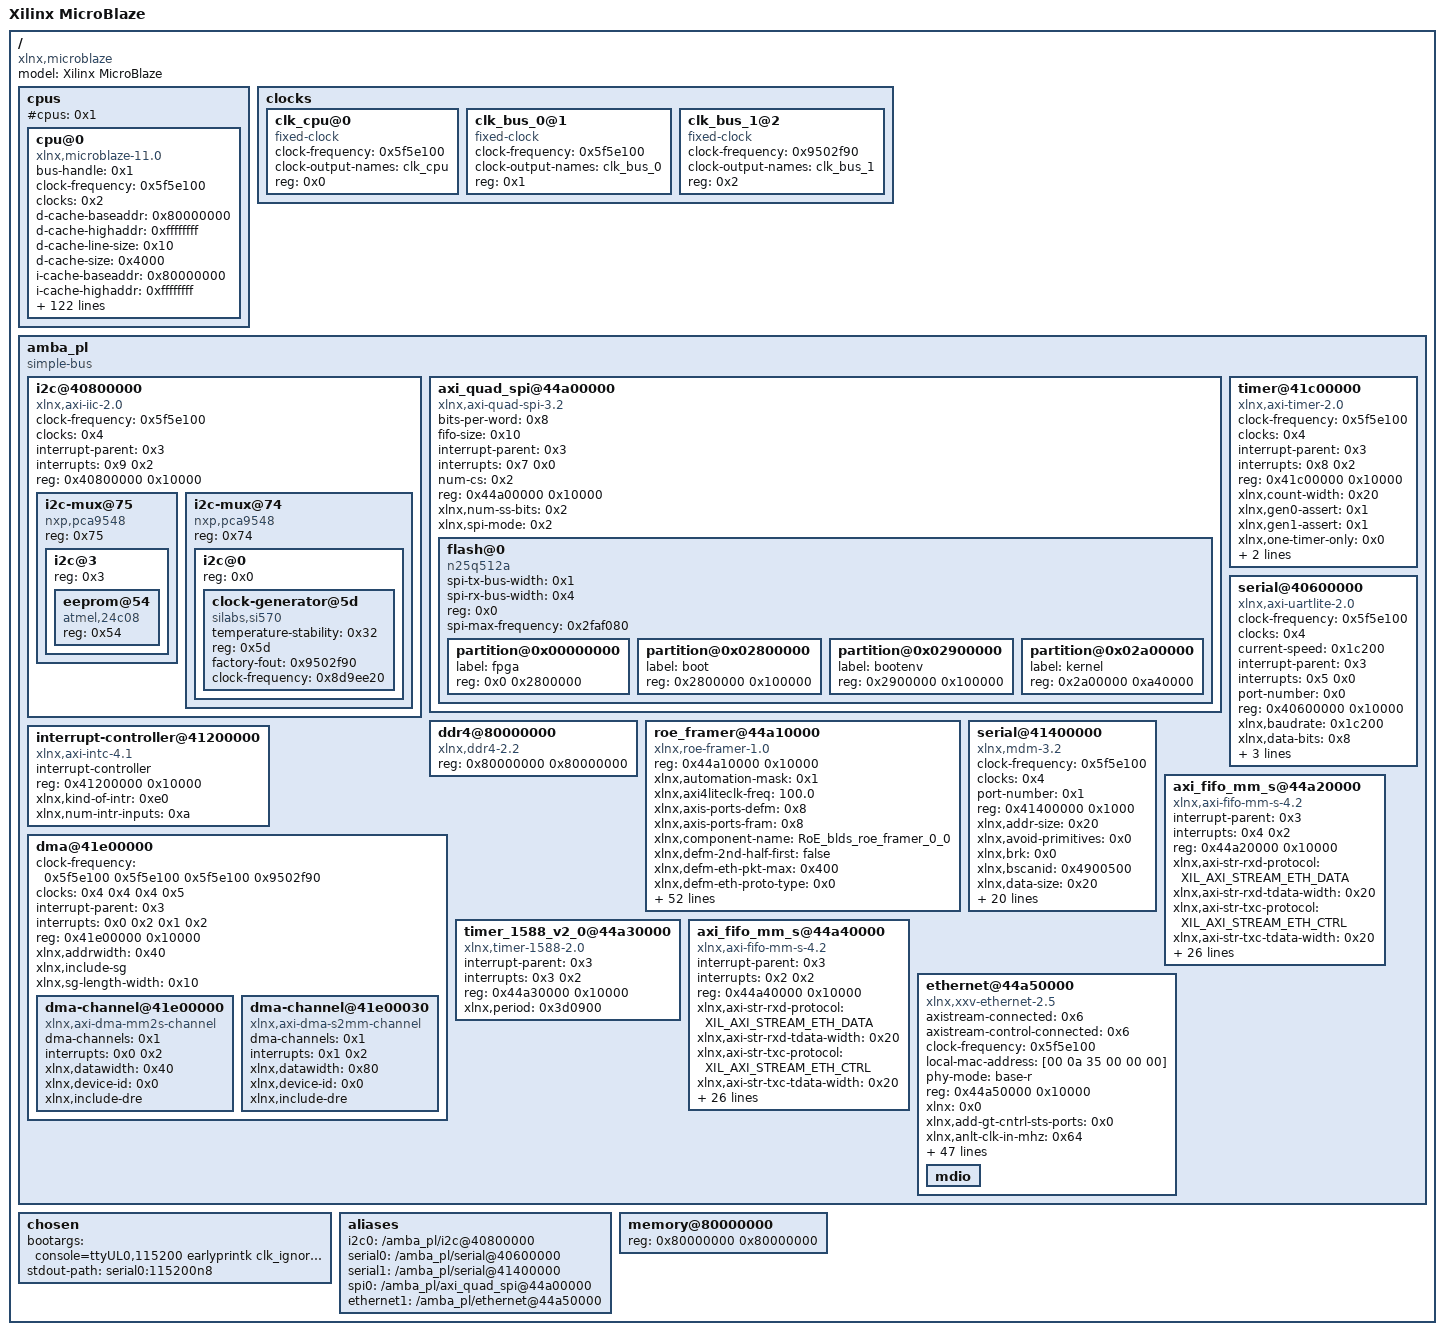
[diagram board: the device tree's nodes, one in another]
/dts-v1/;

/ {
	#address-cells = <0x1>;
	#size-cells = <0x1>;
	compatible = "xlnx,microblaze";
	model = "Xilinx MicroBlaze";

	cpus {
		#address-cells = <0x1>;
		#cpus = <0x1>;
		#size-cells = <0x0>;

		cpu@0 {
			bus-handle = <0x1>;
			clock-frequency = <0x5f5e100>;
			clocks = <0x2>;
			compatible = "xlnx,microblaze-11.0";
			d-cache-baseaddr = <0x80000000>;
			d-cache-highaddr = <0xffffffff>;
			d-cache-line-size = <0x10>;
			d-cache-size = <0x4000>;
			device_type = "cpu";
			i-cache-baseaddr = <0x80000000>;
			i-cache-highaddr = <0xffffffff>;
			i-cache-line-size = <0x20>;
			i-cache-size = <0x4000>;
			interrupt-handle = <0x3>;
			model = "microblaze,11.0";
			reg = <0x0>;
			timebase-frequency = <0x5f5e100>;
			xlnx,addr-size = <0x20>;
			xlnx,addr-tag-bits = <0x11>;
			xlnx,allow-dcache-wr = <0x1>;
			xlnx,allow-icache-wr = <0x1>;
			xlnx,area-optimized = <0x0>;
			xlnx,async-interrupt = <0x1>;
			xlnx,async-wakeup = <0x3>;
			xlnx,avoid-primitives = <0x0>;
			xlnx,base-vectors = <0x0>;
			xlnx,branch-target-cache-size = <0x0>;
			xlnx,cache-byte-size = <0x4000>;
			xlnx,d-axi = <0x1>;
			xlnx,d-lmb = <0x1>;
			xlnx,d-lmb-mon = <0x0>;
			xlnx,daddr-size = <0x20>;
			xlnx,data-size = <0x20>;
			xlnx,dc-axi-mon = <0x0>;
			xlnx,dcache-addr-tag = <0x11>;
			xlnx,dcache-always-used = <0x1>;
			xlnx,dcache-byte-size = <0x4000>;
			xlnx,dcache-data-width = <0x0>;
			xlnx,dcache-force-tag-lutram = <0x0>;
			xlnx,dcache-line-len = <0x4>;
			xlnx,dcache-use-writeback = <0x0>;
			xlnx,dcache-victims = <0x8>;
			xlnx,debug-counter-width = <0x20>;
			xlnx,debug-enabled = <0x1>;
			xlnx,debug-event-counters = <0x5>;
			xlnx,debug-external-trace = <0x0>;
			xlnx,debug-interface = <0x0>;
			xlnx,debug-latency-counters = <0x1>;
			xlnx,debug-profile-size = <0x0>;
			xlnx,debug-trace-async-reset = <0x0>;
			xlnx,debug-trace-size = <0x2000>;
			xlnx,div-zero-exception = <0x1>;
			xlnx,dp-axi-mon = <0x0>;
			xlnx,dynamic-bus-sizing = <0x0>;
			xlnx,ecc-use-ce-exception = <0x0>;
			xlnx,edge-is-positive = <0x1>;
			xlnx,enable-discrete-ports = <0x0>;
			xlnx,endianness = <0x1>;
			xlnx,fault-tolerant = <0x1>;
			xlnx,fpu-exception = <0x0>;
			xlnx,freq = <0x5f5e100>;
			xlnx,fsl-exception = <0x0>;
			xlnx,fsl-links = <0x0>;
			xlnx,i-axi = <0x1>;
			xlnx,i-lmb = <0x1>;
			xlnx,i-lmb-mon = <0x0>;
			xlnx,iaddr-size = <0x20>;
			xlnx,ic-axi-mon = <0x0>;
			xlnx,icache-always-used = <0x1>;
			xlnx,icache-data-width = <0x0>;
			xlnx,icache-force-tag-lutram = <0x0>;
			xlnx,icache-line-len = <0x8>;
			xlnx,icache-streams = <0x1>;
			xlnx,icache-victims = <0x8>;
			xlnx,ill-opcode-exception = <0x1>;
			xlnx,imprecise-exceptions = <0x0>;
			xlnx,instr-size = <0x20>;
			xlnx,interconnect = <0x2>;
			xlnx,interrupt-is-edge = <0x0>;
			xlnx,interrupt-mon = <0x0>;
			xlnx,ip-axi-mon = <0x0>;
			xlnx,lmb-data-size = <0x20>;
			xlnx,lockstep-master = <0x0>;
			xlnx,lockstep-select = <0x0>;
			xlnx,lockstep-slave = <0x0>;
			xlnx,mmu-dtlb-size = <0x4>;
			xlnx,mmu-itlb-size = <0x2>;
			xlnx,mmu-privileged-instr = <0x0>;
			xlnx,mmu-tlb-access = <0x3>;
			xlnx,mmu-zones = <0x2>;
			xlnx,num-sync-ff-clk = <0x2>;
			xlnx,num-sync-ff-clk-debug = <0x2>;
			xlnx,num-sync-ff-clk-irq = <0x1>;
			xlnx,num-sync-ff-dbg-clk = <0x1>;
			xlnx,num-sync-ff-dbg-trace-clk = <0x2>;
			xlnx,number-of-pc-brk = <0x1>;
			xlnx,number-of-rd-addr-brk = <0x0>;
			xlnx,number-of-wr-addr-brk = <0x0>;
			xlnx,opcode-0x0-illegal = <0x1>;
			xlnx,optimization = <0x0>;
			xlnx,pc-width = <0x20>;
			xlnx,piaddr-size = <0x20>;
			xlnx,pvr = <0x2>;
			xlnx,pvr-user1 = <0x0>;
			xlnx,pvr-user2 = <0x0>;
			xlnx,reset-msr = <0x0>;
			xlnx,reset-msr-bip = <0x0>;
			xlnx,reset-msr-dce = <0x0>;
			xlnx,reset-msr-ee = <0x0>;
			xlnx,reset-msr-eip = <0x0>;
			xlnx,reset-msr-ice = <0x0>;
			xlnx,reset-msr-ie = <0x0>;
			xlnx,sco = <0x0>;
			xlnx,trace = <0x0>;
			xlnx,unaligned-exceptions = <0x1>;
			xlnx,use-barrel = <0x1>;
			xlnx,use-branch-target-cache = <0x0>;
			xlnx,use-config-reset = <0x0>;
			xlnx,use-dcache = <0x1>;
			xlnx,use-div = <0x1>;
			xlnx,use-ext-brk = <0x0>;
			xlnx,use-ext-nm-brk = <0x0>;
			xlnx,use-extended-fsl-instr = <0x0>;
			xlnx,use-fpu = <0x0>;
			xlnx,use-hw-mul = <0x2>;
			xlnx,use-icache = <0x1>;
			xlnx,use-interrupt = <0x2>;
			xlnx,use-mmu = <0x3>;
			xlnx,use-msr-instr = <0x1>;
			xlnx,use-non-secure = <0x0>;
			xlnx,use-pcmp-instr = <0x1>;
			xlnx,use-reorder-instr = <0x1>;
			xlnx,use-stack-protection = <0x0>;
		};
	};

	clocks {
		#address-cells = <0x1>;
		#size-cells = <0x0>;

		clk_cpu@0 {
			#clock-cells = <0x0>;
			clock-frequency = <0x5f5e100>;
			clock-output-names = "clk_cpu";
			compatible = "fixed-clock";
			reg = <0x0>;
			linux,phandle = <0x2>;
			phandle = <0x2>;
		};

		clk_bus_0@1 {
			#clock-cells = <0x0>;
			clock-frequency = <0x5f5e100>;
			clock-output-names = "clk_bus_0";
			compatible = "fixed-clock";
			reg = <0x1>;
			linux,phandle = <0x4>;
			phandle = <0x4>;
		};

		clk_bus_1@2 {
			#clock-cells = <0x0>;
			clock-frequency = <0x9502f90>;
			clock-output-names = "clk_bus_1";
			compatible = "fixed-clock";
			reg = <0x2>;
			linux,phandle = <0x5>;
			phandle = <0x5>;
		};
	};

	amba_pl {
		#address-cells = <0x1>;
		#size-cells = <0x1>;
		compatible = "simple-bus";
		ranges;
		linux,phandle = <0x1>;
		phandle = <0x1>;

		i2c@40800000 {
			#address-cells = <0x1>;
			#size-cells = <0x0>;
			clock-frequency = <0x5f5e100>;
			clocks = <0x4>;
			compatible = "xlnx,axi-iic-2.0", "xlnx,xps-iic-2.00.a";
			interrupt-names = "iic2intc_irpt";
			interrupt-parent = <0x3>;
			interrupts = <0x9 0x2>;
			reg = <0x40800000 0x10000>;

			i2c-mux@75 {
				compatible = "nxp,pca9548";
				#address-cells = <0x1>;
				#size-cells = <0x0>;
				reg = <0x75>;

				i2c@3 {
					#address-cells = <0x1>;
					#size-cells = <0x0>;
					reg = <0x3>;

					eeprom@54 {
						compatible = "atmel,24c08";
						reg = <0x54>;
					};
				};
			};

			i2c-mux@74 {
				compatible = "nxp,pca9548";
				#address-cells = <0x1>;
				#size-cells = <0x0>;
				reg = <0x74>;

				i2c@0 {
					#address-cells = <0x1>;
					#size-cells = <0x0>;
					reg = <0x0>;

					clock-generator@5d {
						#clock-cells = <0x0>;
						compatible = "silabs,si570";
						temperature-stability = <0x32>;
						reg = <0x5d>;
						factory-fout = <0x9502f90>;
						clock-frequency = <0x8d9ee20>;
					};
				};
			};
		};

		axi_quad_spi@44a00000 {
			bits-per-word = <0x8>;
			compatible = "xlnx,axi-quad-spi-3.2", "xlnx,xps-spi-2.00.a";
			fifo-size = <0x10>;
			interrupt-names = "ip2intc_irpt";
			interrupt-parent = <0x3>;
			interrupts = <0x7 0x0>;
			num-cs = <0x2>;
			reg = <0x44a00000 0x10000>;
			xlnx,num-ss-bits = <0x2>;
			xlnx,spi-mode = <0x2>;
			#address-cells = <0x1>;
			#size-cells = <0x0>;

			flash@0 {
				compatible = "n25q512a", "micron,m25p80", "spi-flash";
				spi-tx-bus-width = <0x1>;
				spi-rx-bus-width = <0x4>;
				reg = <0x0>;
				#address-cells = <0x1>;
				#size-cells = <0x1>;
				spi-max-frequency = <0x2faf080>;

				partition@0x00000000 {
					label = "fpga";
					reg = <0x0 0x2800000>;
				};

				partition@0x02800000 {
					label = "boot";
					reg = <0x2800000 0x100000>;
				};

				partition@0x02900000 {
					label = "bootenv";
					reg = <0x2900000 0x100000>;
				};

				partition@0x02a00000 {
					label = "kernel";
					reg = <0x2a00000 0xa40000>;
				};
			};
		};

		timer@41c00000 {
			clock-frequency = <0x5f5e100>;
			clocks = <0x4>;
			compatible = "xlnx,axi-timer-2.0", "xlnx,xps-timer-1.00.a";
			interrupt-names = "interrupt";
			interrupt-parent = <0x3>;
			interrupts = <0x8 0x2>;
			reg = <0x41c00000 0x10000>;
			xlnx,count-width = <0x20>;
			xlnx,gen0-assert = <0x1>;
			xlnx,gen1-assert = <0x1>;
			xlnx,one-timer-only = <0x0>;
			xlnx,trig0-assert = <0x1>;
			xlnx,trig1-assert = <0x1>;
		};

		serial@40600000 {
			clock-frequency = <0x5f5e100>;
			clocks = <0x4>;
			compatible = "xlnx,axi-uartlite-2.0", "xlnx,xps-uartlite-1.00.a";
			current-speed = <0x1c200>;
			device_type = "serial";
			interrupt-names = "interrupt";
			interrupt-parent = <0x3>;
			interrupts = <0x5 0x0>;
			port-number = <0x0>;
			reg = <0x40600000 0x10000>;
			xlnx,baudrate = <0x1c200>;
			xlnx,data-bits = <0x8>;
			xlnx,odd-parity = <0x0>;
			xlnx,s-axi-aclk-freq-hz-d = "100.0";
			xlnx,use-parity = <0x0>;
		};

		ddr4@80000000 {
			compatible = "xlnx,ddr4-2.2";
			reg = <0x80000000 0x80000000>;
		};

		roe_framer@44a10000 {
			compatible = "xlnx,roe-framer-1.0";
			reg = <0x44a10000 0x10000>;
			xlnx,automation-mask = <0x1>;
			xlnx,axi4liteclk-freq = "100.0";
			xlnx,axis-ports-defm = <0x8>;
			xlnx,axis-ports-fram = <0x8>;
			xlnx,component-name = "RoE_blds_roe_framer_0_0";
			xlnx,defm-2nd-half-first = "false";
			xlnx,defm-eth-pkt-max = <0x400>;
			xlnx,defm-eth-proto-type = <0x0>;
			xlnx,defm-ext-srf = "true";
			xlnx,defm-fd-en = "false";
			xlnx,defm-high-l-sn-cnt-pres = "false";
			xlnx,defm-high-l-sn-cnt-width = <0x10>;
			xlnx,defm-ipv4-dest-addr = <0x0>;
			xlnx,defm-ipv4-source-addr = <0x0>;
			xlnx,defm-ipv6-dest-addr = <0x0>;
			xlnx,defm-ipv6-source-addr = <0x0>;
			xlnx,defm-low-l-sn-cnt-pos = "false";
			xlnx,defm-low-l-sn-cnt-width = <0x10>;
			xlnx,defm-pdu = <0x400>;
			xlnx,defm-pkt-x-pdu = <0x1>;
			xlnx,defm-rtc-en = "false";
			xlnx,defm-rtc-len = <0x3c>;
			xlnx,defm-rwin = <0x1>;
			xlnx,defm-sn-reserved-bits = <0x0>;
			xlnx,defm-type2-mac-dest-addr = <0x0>;
			xlnx,defm-type2-mac-source-addr = <0x0>;
			xlnx,defm-vlan-enable = "false";
			xlnx,defm-vlantagcontent = <0x0>;
			xlnx,defmantennaclk-freq = "10.0";
			xlnx,externautomationtclargs = <0x0>;
			xlnx,externautomationtclscr = <0x0>;
			xlnx,fram-auto-start = "true";
			xlnx,fram-eth-pkt-max = <0x400>;
			xlnx,fram-eth-proto-type = <0x0>;
			xlnx,fram-ext-srf = "true";
			xlnx,fram-fd-en = "false";
			xlnx,fram-high-l-sn-cnt-pres = "false";
			xlnx,fram-high-l-sn-cnt-width = <0x10>;
			xlnx,fram-ipv4-dest-addr = <0x0>;
			xlnx,fram-ipv4-source-addr = <0x0>;
			xlnx,fram-ipv6-dest-addr = <0x0>;
			xlnx,fram-ipv6-source-addr = <0x0>;
			xlnx,fram-low-l-sn-cnt-pos = "false";
			xlnx,fram-low-l-sn-cnt-width = <0x10>;
			xlnx,fram-pdu = <0x400>;
			xlnx,fram-rtc-en = "false";
			xlnx,fram-rtc-len = <0x3c>;
			xlnx,fram-sn-reserved-bits = <0x0>;
			xlnx,fram-type2-mac-dest-addr = <0x0>;
			xlnx,fram-type2-mac-source-addr = <0x0>;
			xlnx,fram-vlan-enable = "false";
			xlnx,fram-vlantagcontent = <0x0>;
			xlnx,framantennaclk-freq = "10.0";
			xlnx,internal-bist-mode = <0x0>;
			xlnx,internalclk-freq = "156.25";
			xlnx,physical-ethernet-ports = <0x1>;
			xlnx,physical-ethernet-rate = "10G";
			xlnx,production-simulation = <0x0>;
			xlnx,tsn-support = <0x0>;
			xlnx,user-gpio-enable = "true";
		};

		serial@41400000 {
			clock-frequency = <0x5f5e100>;
			clocks = <0x4>;
			compatible = "xlnx,mdm-3.2", "xlnx,xps-uartlite-1.00.a";
			device_type = "serial";
			port-number = <0x1>;
			reg = <0x41400000 0x1000>;
			xlnx,addr-size = <0x20>;
			xlnx,avoid-primitives = <0x0>;
			xlnx,brk = <0x0>;
			xlnx,bscanid = <0x4900500>;
			xlnx,data-size = <0x20>;
			xlnx,dbg-mem-access = <0x0>;
			xlnx,dbg-reg-access = <0x0>;
			xlnx,debug-interface = <0x0>;
			xlnx,ext-trig-reset-value = <0xf1234>;
			xlnx,interconnect = <0x2>;
			xlnx,jtag-chain = <0x2>;
			xlnx,mb-dbg-ports = <0x1>;
			xlnx,trace-async-reset = <0x0>;
			xlnx,trace-clk-out-phase = <0x5a>;
			xlnx,trace-data-width = <0x20>;
			xlnx,trace-id = <0x6e>;
			xlnx,trace-output = <0x0>;
			xlnx,trace-protocol = <0x1>;
			xlnx,trig-in-ports = <0x1>;
			xlnx,trig-out-ports = <0x1>;
			xlnx,use-bscan = <0x0>;
			xlnx,use-config-reset = <0x0>;
			xlnx,use-cross-trigger = <0x0>;
			xlnx,use-uart = <0x1>;
			xlnx,xmtc = <0x0>;
		};

		interrupt-controller@41200000 {
			#interrupt-cells = <0x2>;
			compatible = "xlnx,axi-intc-4.1", "xlnx,xps-intc-1.00.a";
			interrupt-controller;
			reg = <0x41200000 0x10000>;
			xlnx,kind-of-intr = <0xe0>;
			xlnx,num-intr-inputs = <0xa>;
			linux,phandle = <0x3>;
			phandle = <0x3>;
		};

		dma@41e00000 {
			#dma-cells = <0x1>;
			clock-frequency = <0x5f5e100 0x5f5e100 0x5f5e100 0x9502f90>;
			clock-names = "s_axi_lite_aclk", "m_axi_sg_aclk", "m_axi_mm2s_aclk", "m_axi_s2mm_aclk";
			clocks = <0x4 0x4 0x4 0x5>;
			compatible = [00];
			interrupt-names = "mm2s_introut", "s2mm_introut";
			interrupt-parent = <0x3>;
			interrupts = <0x0 0x2 0x1 0x2>;
			reg = <0x41e00000 0x10000>;
			xlnx,addrwidth = <0x40>;
			xlnx,include-sg;
			xlnx,sg-length-width = <0x10>;
			linux,phandle = <0x6>;
			phandle = <0x6>;

			dma-channel@41e00000 {
				compatible = "xlnx,axi-dma-mm2s-channel";
				dma-channels = <0x1>;
				interrupts = <0x0 0x2>;
				xlnx,datawidth = <0x40>;
				xlnx,device-id = <0x0>;
				xlnx,include-dre;
			};

			dma-channel@41e00030 {
				compatible = "xlnx,axi-dma-s2mm-channel";
				dma-channels = <0x1>;
				interrupts = <0x1 0x2>;
				xlnx,datawidth = <0x80>;
				xlnx,device-id = <0x0>;
				xlnx,include-dre;
			};
		};

		axi_fifo_mm_s@44a20000 {
			compatible = "xlnx,axi-fifo-mm-s-4.2";
			interrupt-names = "interrupt";
			interrupt-parent = <0x3>;
			interrupts = <0x4 0x2>;
			reg = <0x44a20000 0x10000>;
			xlnx,axi-str-rxd-protocol = "XIL_AXI_STREAM_ETH_DATA";
			xlnx,axi-str-rxd-tdata-width = <0x20>;
			xlnx,axi-str-txc-protocol = "XIL_AXI_STREAM_ETH_CTRL";
			xlnx,axi-str-txc-tdata-width = <0x20>;
			xlnx,axi-str-txd-protocol = "XIL_AXI_STREAM_ETH_DATA";
			xlnx,axi-str-txd-tdata-width = <0x20>;
			xlnx,axis-tdest-width = <0x4>;
			xlnx,axis-tid-width = <0x4>;
			xlnx,axis-tuser-width = <0x4>;
			xlnx,data-interface-type = <0x0>;
			xlnx,has-axis-tdest = <0x0>;
			xlnx,has-axis-tid = <0x0>;
			xlnx,has-axis-tkeep = <0x0>;
			xlnx,has-axis-tstrb = <0x0>;
			xlnx,has-axis-tuser = <0x0>;
			xlnx,rx-fifo-depth = <0x200>;
			xlnx,rx-fifo-pe-threshold = <0x5>;
			xlnx,rx-fifo-pf-threshold = <0x1fb>;
			xlnx,s-axi-id-width = <0x4>;
			xlnx,s-axi4-data-width = <0x20>;
			xlnx,select-xpm = <0x0>;
			xlnx,tx-fifo-depth = <0x200>;
			xlnx,tx-fifo-pe-threshold = <0x5>;
			xlnx,tx-fifo-pf-threshold = <0x1fb>;
			xlnx,use-rx-cut-through = <0x0>;
			xlnx,use-rx-data = <0x1>;
			xlnx,use-tx-ctrl = <0x0>;
			xlnx,use-tx-cut-through = <0x0>;
			xlnx,use-tx-data = <0x0>;
			linux,phandle = <0x8>;
			phandle = <0x8>;
		};

		timer_1588_v2_0@44a30000 {
			compatible = "xlnx,timer-1588-2.0";
			interrupt-names = "interrupt";
			interrupt-parent = <0x3>;
			interrupts = <0x3 0x2>;
			reg = <0x44a30000 0x10000>;
			xlnx,period = <0x3d0900>;
		};

		axi_fifo_mm_s@44a40000 {
			compatible = "xlnx,axi-fifo-mm-s-4.2";
			interrupt-names = "interrupt";
			interrupt-parent = <0x3>;
			interrupts = <0x2 0x2>;
			reg = <0x44a40000 0x10000>;
			xlnx,axi-str-rxd-protocol = "XIL_AXI_STREAM_ETH_DATA";
			xlnx,axi-str-rxd-tdata-width = <0x20>;
			xlnx,axi-str-txc-protocol = "XIL_AXI_STREAM_ETH_CTRL";
			xlnx,axi-str-txc-tdata-width = <0x20>;
			xlnx,axi-str-txd-protocol = "XIL_AXI_STREAM_ETH_DATA";
			xlnx,axi-str-txd-tdata-width = <0x20>;
			xlnx,axis-tdest-width = <0x4>;
			xlnx,axis-tid-width = <0x4>;
			xlnx,axis-tuser-width = <0x4>;
			xlnx,data-interface-type = <0x0>;
			xlnx,has-axis-tdest = <0x0>;
			xlnx,has-axis-tid = <0x0>;
			xlnx,has-axis-tkeep = <0x0>;
			xlnx,has-axis-tstrb = <0x0>;
			xlnx,has-axis-tuser = <0x0>;
			xlnx,rx-fifo-depth = <0x200>;
			xlnx,rx-fifo-pe-threshold = <0x5>;
			xlnx,rx-fifo-pf-threshold = <0x1fb>;
			xlnx,s-axi-id-width = <0x4>;
			xlnx,s-axi4-data-width = <0x20>;
			xlnx,select-xpm = <0x0>;
			xlnx,tx-fifo-depth = <0x200>;
			xlnx,tx-fifo-pe-threshold = <0x5>;
			xlnx,tx-fifo-pf-threshold = <0x1fb>;
			xlnx,use-rx-cut-through = <0x0>;
			xlnx,use-rx-data = <0x1>;
			xlnx,use-tx-ctrl = <0x0>;
			xlnx,use-tx-cut-through = <0x0>;
			xlnx,use-tx-data = <0x1>;
			linux,phandle = <0x7>;
			phandle = <0x7>;
		};

		ethernet@44a50000 {
			axistream-connected = <0x6>;
			axistream-control-connected = <0x6>;
			clock-frequency = <0x5f5e100>;
			compatible = "xlnx,xxv-ethernet-2.5", "xlnx,xxv-ethernet-1.0";
			device_type = "network";
			local-mac-address = [00 0a 35 00 00 00];
			phy-mode = "base-r";
			reg = <0x44a50000 0x10000>;
			xlnx = <0x0>;
			xlnx,add-gt-cntrl-sts-ports = <0x0>;
			xlnx,anlt-clk-in-mhz = <0x64>;
			xlnx,axis-tdata-width = <0x40>;
			xlnx,axis-tkeep-width = <0x7>;
			xlnx,base-r-kr = "BASE-R";
			xlnx,clocking = "Asynchronous";
			xlnx,core = "Ethernet MAC+PCS/PMA 64-bit";
			xlnx,data-path-interface = "AXI Stream";
			xlnx,enable-datapath-parity = <0x0>;
			xlnx,enable-pipeline-reg = <0x0>;
			xlnx,enable-preemption = <0x0>;
			xlnx,enable-preemption-fifo = <0x0>;
			xlnx,enable-rx-flow-control-logic = <0x0>;
			xlnx,enable-time-stamping = <0x1>;
			xlnx,enable-tx-flow-control-logic = <0x0>;
			xlnx,enable-vlane-adjust-mode = <0x0>;
			xlnx,family-chk = "virtexuplus";
			xlnx,fast-sim-mode = <0x0>;
			xlnx,gt-diffctrl-width = <0x4>;
			xlnx,gt-drp-clk = "100.00";
			xlnx,gt-group-select = "Quad X0Y0";
			xlnx,gt-location = <0x1>;
			xlnx,gt-ref-clk-freq = "156.25";
			xlnx,gt-type = "GTY";
			xlnx,include-auto-neg-lt-logic = "None";
			xlnx,include-axi4-interface = <0x1>;
			xlnx,include-dre;
			xlnx,include-fec-logic = <0x0>;
			xlnx,include-rsfec-logic = <0x0>;
			xlnx,include-shared-logic = <0x1>;
			xlnx,include-user-fifo = <0x1>;
			xlnx,lane1-gt-loc = "X1Y48";
			xlnx,lane2-gt-loc = "NA";
			xlnx,lane3-gt-loc = "NA";
			xlnx,lane4-gt-loc = "NA";
			xlnx,line-rate = <0xa>;
			xlnx,mii-ctrl-width = <0x4>;
			xlnx,mii-data-width = <0x20>;
			xlnx,num-of-cores = <0x1>;
			xlnx,ptp-clocking-mode = <0x0>;
			xlnx,ptp-operation-mode = <0x2>;
			xlnx,runtime-switch = <0x0>;
			xlnx,rxmem = <0x2580>;
			xlnx,switch-1-10-25g = <0x0>;
			xlnx,tx-latency-adjust = <0x0>;
			xlnx,tx-total-bytes-width = <0x4>;
			xlnx,xgmii-interface = <0x1>;
			axififo-connected = <0x7>;
			xlnx,rxtsfifo = <0x8>;

			mdio {
				#address-cells = <0x1>;
				#size-cells = <0x0>;
			};
		};
	};

	chosen {
		bootargs = "console=ttyUL0,115200 earlyprintk clk_ignore_unused cpuidle.off=1 uio_pdrv_genirq.of_id=generic-uio mem=5G";
		stdout-path = "serial0:115200n8";
	};

	aliases {
		i2c0 = "/amba_pl/i2c@40800000";
		serial0 = "/amba_pl/serial@40600000";
		serial1 = "/amba_pl/serial@41400000";
		spi0 = "/amba_pl/axi_quad_spi@44a00000";
		ethernet1 = "/amba_pl/ethernet@44a50000";
	};

	memory@80000000 {
		device_type = "memory";
		reg = <0x80000000 0x80000000>;
	};
};
